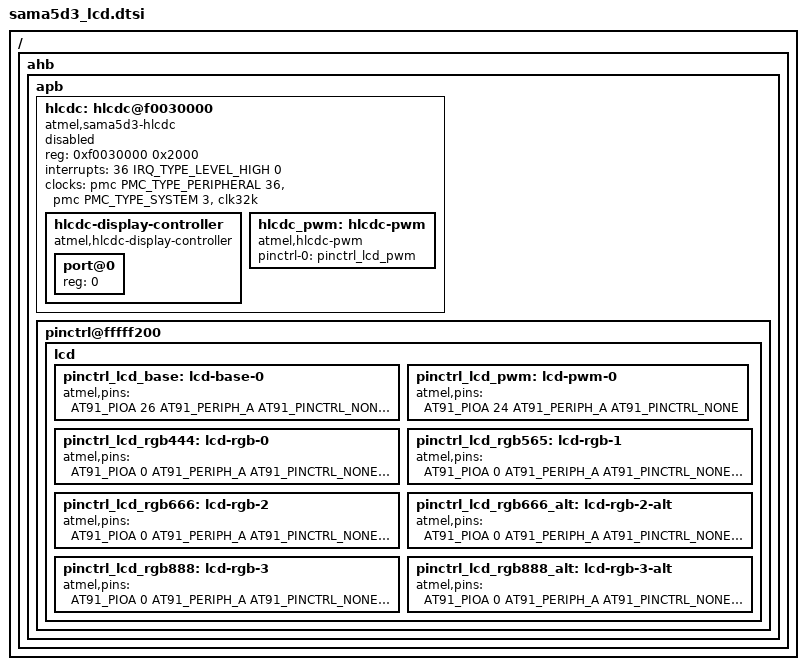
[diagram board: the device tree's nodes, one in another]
#include <dt-bindings/pinctrl/at91.h>
#include <dt-bindings/interrupt-controller/irq.h>
/ {
	ahb {
		apb {
			hlcdc: hlcdc@f0030000 {
				compatible = "atmel,sama5d3-hlcdc";
				reg = <0xf0030000 0x2000>;
				interrupts = <36 IRQ_TYPE_LEVEL_HIGH 0>;
				clocks = <&pmc PMC_TYPE_PERIPHERAL 36>, <&pmc PMC_TYPE_SYSTEM 3>, <&clk32k>;
				clock-names = "periph_clk","sys_clk", "slow_clk";
				status = "disabled";
				hlcdc-display-controller {
					compatible = "atmel,hlcdc-display-controller";
					#address-cells = <1>;
					#size-cells = <0>;
					port@0 {
						#address-cells = <1>;
						#size-cells = <0>;
						reg = <0>;
					};
				};
				hlcdc_pwm: hlcdc-pwm {
					compatible = "atmel,hlcdc-pwm";
					pinctrl-names = "default";
					pinctrl-0 = <&pinctrl_lcd_pwm>;
					#pwm-cells = <3>;
				};
			};
			pinctrl@fffff200 {
				lcd {
					pinctrl_lcd_base: lcd-base-0 {
						atmel,pins =
							<AT91_PIOA 26 AT91_PERIPH_A AT91_PINCTRL_NONE	 
							 AT91_PIOA 27 AT91_PERIPH_A AT91_PINCTRL_NONE	 
							 AT91_PIOA 25 AT91_PERIPH_A AT91_PINCTRL_NONE	 
							 AT91_PIOA 29 AT91_PERIPH_A AT91_PINCTRL_NONE	 
							 AT91_PIOA 28 AT91_PERIPH_A AT91_PINCTRL_NONE>;	 
					};
					pinctrl_lcd_pwm: lcd-pwm-0 {
						atmel,pins = <AT91_PIOA 24 AT91_PERIPH_A AT91_PINCTRL_NONE>;	 
					};
					pinctrl_lcd_rgb444: lcd-rgb-0 {
						atmel,pins =
							<AT91_PIOA 0 AT91_PERIPH_A AT91_PINCTRL_NONE	 
							 AT91_PIOA 1 AT91_PERIPH_A AT91_PINCTRL_NONE	 
							 AT91_PIOA 2 AT91_PERIPH_A AT91_PINCTRL_NONE	 
							 AT91_PIOA 3 AT91_PERIPH_A AT91_PINCTRL_NONE	 
							 AT91_PIOA 4 AT91_PERIPH_A AT91_PINCTRL_NONE	 
							 AT91_PIOA 5 AT91_PERIPH_A AT91_PINCTRL_NONE	 
							 AT91_PIOA 6 AT91_PERIPH_A AT91_PINCTRL_NONE	 
							 AT91_PIOA 7 AT91_PERIPH_A AT91_PINCTRL_NONE	 
							 AT91_PIOA 8 AT91_PERIPH_A AT91_PINCTRL_NONE	 
							 AT91_PIOA 9 AT91_PERIPH_A AT91_PINCTRL_NONE	 
							 AT91_PIOA 10 AT91_PERIPH_A AT91_PINCTRL_NONE	 
							 AT91_PIOA 11 AT91_PERIPH_A AT91_PINCTRL_NONE>;	 
					};
					pinctrl_lcd_rgb565: lcd-rgb-1 {
						atmel,pins =
							<AT91_PIOA 0 AT91_PERIPH_A AT91_PINCTRL_NONE	 
							 AT91_PIOA 1 AT91_PERIPH_A AT91_PINCTRL_NONE	 
							 AT91_PIOA 2 AT91_PERIPH_A AT91_PINCTRL_NONE	 
							 AT91_PIOA 3 AT91_PERIPH_A AT91_PINCTRL_NONE	 
							 AT91_PIOA 4 AT91_PERIPH_A AT91_PINCTRL_NONE	 
							 AT91_PIOA 5 AT91_PERIPH_A AT91_PINCTRL_NONE	 
							 AT91_PIOA 6 AT91_PERIPH_A AT91_PINCTRL_NONE	 
							 AT91_PIOA 7 AT91_PERIPH_A AT91_PINCTRL_NONE	 
							 AT91_PIOA 8 AT91_PERIPH_A AT91_PINCTRL_NONE	 
							 AT91_PIOA 9 AT91_PERIPH_A AT91_PINCTRL_NONE	 
							 AT91_PIOA 10 AT91_PERIPH_A AT91_PINCTRL_NONE	 
							 AT91_PIOA 11 AT91_PERIPH_A AT91_PINCTRL_NONE	 
							 AT91_PIOA 12 AT91_PERIPH_A AT91_PINCTRL_NONE	 
							 AT91_PIOA 13 AT91_PERIPH_A AT91_PINCTRL_NONE	 
							 AT91_PIOA 14 AT91_PERIPH_A AT91_PINCTRL_NONE	 
							 AT91_PIOA 15 AT91_PERIPH_A AT91_PINCTRL_NONE>;	 
					};
					pinctrl_lcd_rgb666: lcd-rgb-2 {
						atmel,pins =
							<AT91_PIOA 0 AT91_PERIPH_A AT91_PINCTRL_NONE	 
							 AT91_PIOA 1 AT91_PERIPH_A AT91_PINCTRL_NONE	 
							 AT91_PIOA 2 AT91_PERIPH_A AT91_PINCTRL_NONE	 
							 AT91_PIOA 3 AT91_PERIPH_A AT91_PINCTRL_NONE	 
							 AT91_PIOA 4 AT91_PERIPH_A AT91_PINCTRL_NONE	 
							 AT91_PIOA 5 AT91_PERIPH_A AT91_PINCTRL_NONE	 
							 AT91_PIOA 6 AT91_PERIPH_A AT91_PINCTRL_NONE	 
							 AT91_PIOA 7 AT91_PERIPH_A AT91_PINCTRL_NONE	 
							 AT91_PIOA 8 AT91_PERIPH_A AT91_PINCTRL_NONE	 
							 AT91_PIOA 9 AT91_PERIPH_A AT91_PINCTRL_NONE	 
							 AT91_PIOA 10 AT91_PERIPH_A AT91_PINCTRL_NONE	 
							 AT91_PIOA 11 AT91_PERIPH_A AT91_PINCTRL_NONE	 
							 AT91_PIOA 12 AT91_PERIPH_A AT91_PINCTRL_NONE	 
							 AT91_PIOA 13 AT91_PERIPH_A AT91_PINCTRL_NONE	 
							 AT91_PIOA 14 AT91_PERIPH_A AT91_PINCTRL_NONE	 
							 AT91_PIOA 15 AT91_PERIPH_A AT91_PINCTRL_NONE	 
							 AT91_PIOA 16 AT91_PERIPH_A AT91_PINCTRL_NONE	 
							 AT91_PIOA 17 AT91_PERIPH_A AT91_PINCTRL_NONE>;	 
					};
					pinctrl_lcd_rgb666_alt: lcd-rgb-2-alt {
						atmel,pins =
							<AT91_PIOA 0 AT91_PERIPH_A AT91_PINCTRL_NONE	 
							 AT91_PIOA 1 AT91_PERIPH_A AT91_PINCTRL_NONE	 
							 AT91_PIOA 2 AT91_PERIPH_A AT91_PINCTRL_NONE	 
							 AT91_PIOA 3 AT91_PERIPH_A AT91_PINCTRL_NONE	 
							 AT91_PIOA 4 AT91_PERIPH_A AT91_PINCTRL_NONE	 
							 AT91_PIOA 5 AT91_PERIPH_A AT91_PINCTRL_NONE	 
							 AT91_PIOA 6 AT91_PERIPH_A AT91_PINCTRL_NONE	 
							 AT91_PIOA 7 AT91_PERIPH_A AT91_PINCTRL_NONE	 
							 AT91_PIOA 8 AT91_PERIPH_A AT91_PINCTRL_NONE	 
							 AT91_PIOA 9 AT91_PERIPH_A AT91_PINCTRL_NONE	 
							 AT91_PIOA 10 AT91_PERIPH_A AT91_PINCTRL_NONE	 
							 AT91_PIOA 11 AT91_PERIPH_A AT91_PINCTRL_NONE	 
							 AT91_PIOA 12 AT91_PERIPH_A AT91_PINCTRL_NONE	 
							 AT91_PIOA 13 AT91_PERIPH_A AT91_PINCTRL_NONE	 
							 AT91_PIOA 14 AT91_PERIPH_A AT91_PINCTRL_NONE	 
							 AT91_PIOA 15 AT91_PERIPH_A AT91_PINCTRL_NONE	 
							 AT91_PIOC 14 AT91_PERIPH_C AT91_PINCTRL_NONE	 
							 AT91_PIOC 13 AT91_PERIPH_C AT91_PINCTRL_NONE>;	 
					};
					pinctrl_lcd_rgb888: lcd-rgb-3 {
						atmel,pins =
							<AT91_PIOA 0 AT91_PERIPH_A AT91_PINCTRL_NONE	 
							 AT91_PIOA 1 AT91_PERIPH_A AT91_PINCTRL_NONE	 
							 AT91_PIOA 2 AT91_PERIPH_A AT91_PINCTRL_NONE	 
							 AT91_PIOA 3 AT91_PERIPH_A AT91_PINCTRL_NONE	 
							 AT91_PIOA 4 AT91_PERIPH_A AT91_PINCTRL_NONE	 
							 AT91_PIOA 5 AT91_PERIPH_A AT91_PINCTRL_NONE	 
							 AT91_PIOA 6 AT91_PERIPH_A AT91_PINCTRL_NONE	 
							 AT91_PIOA 7 AT91_PERIPH_A AT91_PINCTRL_NONE	 
							 AT91_PIOA 8 AT91_PERIPH_A AT91_PINCTRL_NONE	 
							 AT91_PIOA 9 AT91_PERIPH_A AT91_PINCTRL_NONE	 
							 AT91_PIOA 10 AT91_PERIPH_A AT91_PINCTRL_NONE	 
							 AT91_PIOA 11 AT91_PERIPH_A AT91_PINCTRL_NONE	 
							 AT91_PIOA 12 AT91_PERIPH_A AT91_PINCTRL_NONE	 
							 AT91_PIOA 13 AT91_PERIPH_A AT91_PINCTRL_NONE	 
							 AT91_PIOA 14 AT91_PERIPH_A AT91_PINCTRL_NONE	 
							 AT91_PIOA 15 AT91_PERIPH_A AT91_PINCTRL_NONE	 
							 AT91_PIOA 16 AT91_PERIPH_A AT91_PINCTRL_NONE	 
							 AT91_PIOA 17 AT91_PERIPH_A AT91_PINCTRL_NONE	 
							 AT91_PIOA 18 AT91_PERIPH_A AT91_PINCTRL_NONE	 
							 AT91_PIOA 19 AT91_PERIPH_A AT91_PINCTRL_NONE	 
							 AT91_PIOA 20 AT91_PERIPH_A AT91_PINCTRL_NONE	 
							 AT91_PIOA 21 AT91_PERIPH_A AT91_PINCTRL_NONE	 
							 AT91_PIOA 22 AT91_PERIPH_A AT91_PINCTRL_NONE	 
							 AT91_PIOA 23 AT91_PERIPH_A AT91_PINCTRL_NONE>;	 
					};
					pinctrl_lcd_rgb888_alt: lcd-rgb-3-alt {
						atmel,pins =
							<AT91_PIOA 0 AT91_PERIPH_A AT91_PINCTRL_NONE	 
							 AT91_PIOA 1 AT91_PERIPH_A AT91_PINCTRL_NONE	 
							 AT91_PIOA 2 AT91_PERIPH_A AT91_PINCTRL_NONE	 
							 AT91_PIOA 3 AT91_PERIPH_A AT91_PINCTRL_NONE	 
							 AT91_PIOA 4 AT91_PERIPH_A AT91_PINCTRL_NONE	 
							 AT91_PIOA 5 AT91_PERIPH_A AT91_PINCTRL_NONE	 
							 AT91_PIOA 6 AT91_PERIPH_A AT91_PINCTRL_NONE	 
							 AT91_PIOA 7 AT91_PERIPH_A AT91_PINCTRL_NONE	 
							 AT91_PIOA 8 AT91_PERIPH_A AT91_PINCTRL_NONE	 
							 AT91_PIOA 9 AT91_PERIPH_A AT91_PINCTRL_NONE	 
							 AT91_PIOA 10 AT91_PERIPH_A AT91_PINCTRL_NONE	 
							 AT91_PIOA 11 AT91_PERIPH_A AT91_PINCTRL_NONE	 
							 AT91_PIOA 12 AT91_PERIPH_A AT91_PINCTRL_NONE	 
							 AT91_PIOA 13 AT91_PERIPH_A AT91_PINCTRL_NONE	 
							 AT91_PIOA 14 AT91_PERIPH_A AT91_PINCTRL_NONE	 
							 AT91_PIOA 15 AT91_PERIPH_A AT91_PINCTRL_NONE	 
							 AT91_PIOC 14 AT91_PERIPH_C AT91_PINCTRL_NONE	 
							 AT91_PIOC 13 AT91_PERIPH_C AT91_PINCTRL_NONE	 
							 AT91_PIOC 12 AT91_PERIPH_C AT91_PINCTRL_NONE	 
							 AT91_PIOC 11 AT91_PERIPH_C AT91_PINCTRL_NONE	 
							 AT91_PIOC 10 AT91_PERIPH_C AT91_PINCTRL_NONE	 
							 AT91_PIOC 15 AT91_PERIPH_C AT91_PINCTRL_NONE	 
							 AT91_PIOE 27 AT91_PERIPH_C AT91_PINCTRL_NONE	 
							 AT91_PIOE 28 AT91_PERIPH_C AT91_PINCTRL_NONE>;	 
					};
				};
			};
		};
	};
};
